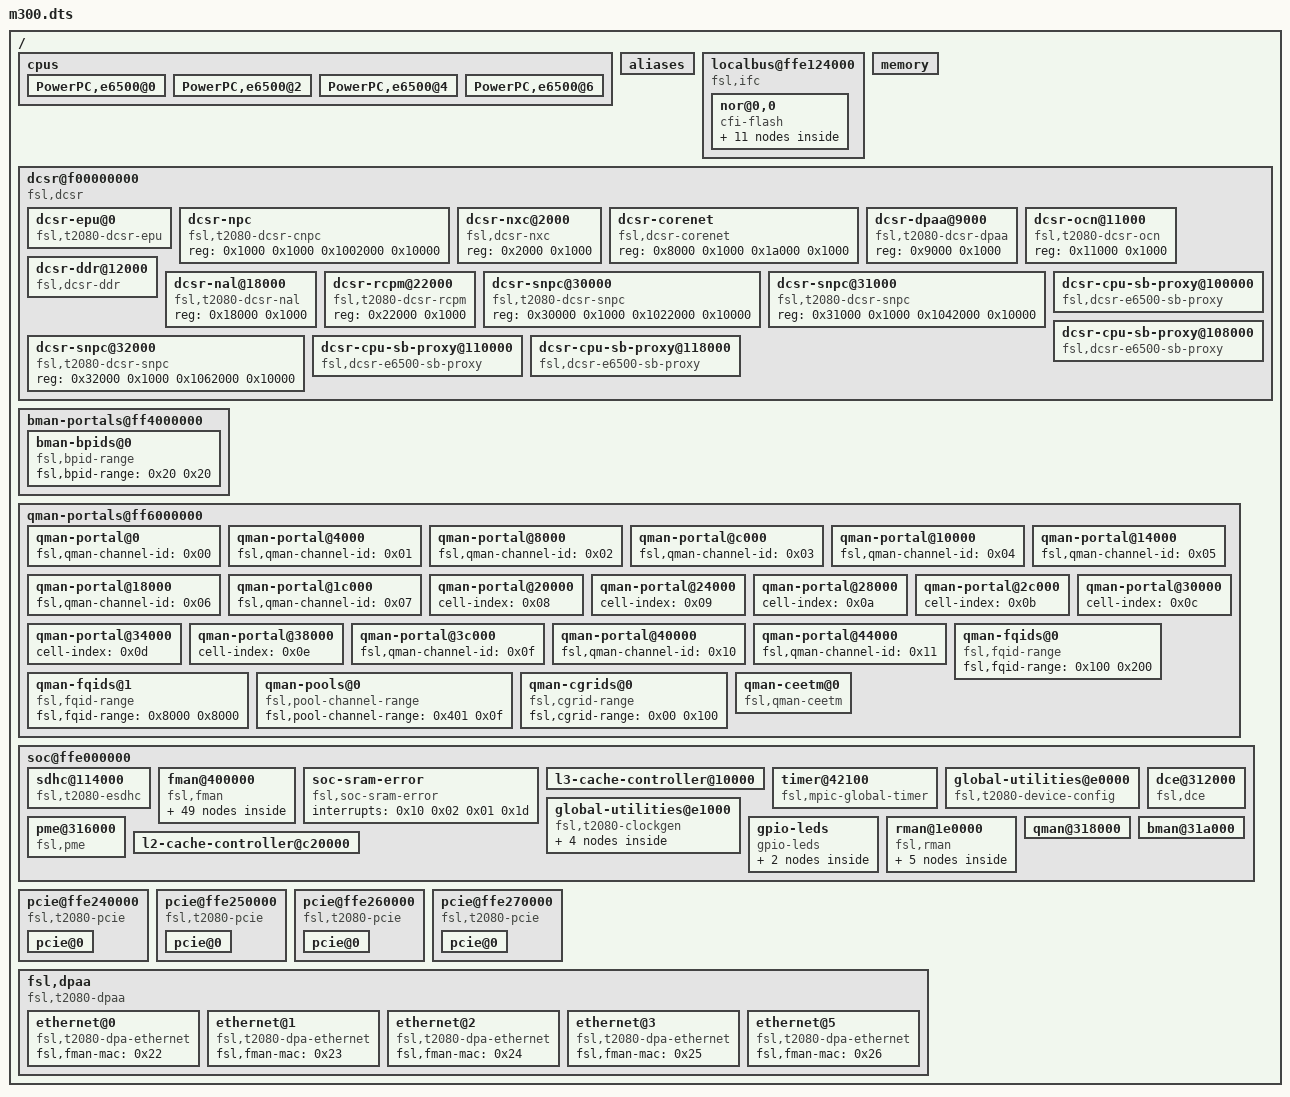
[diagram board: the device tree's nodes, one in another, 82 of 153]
/dts-v1/;

/ {
	cpus {
		PowerPC,e6500@0 {
			device_type = "cpu";
			reg = <0x00 0x01>;
			next-level-cache = <0x03>;
			linux,phandle = <0x05>;
			phandle = <0x05>;
		};

		PowerPC,e6500@2 {
			device_type = "cpu";
			reg = <0x02 0x03>;
			clocks = <0x02>;
			next-level-cache = <0x03>;
			linux,phandle = <0x06>;
			phandle = <0x06>;
		};

		PowerPC,e6500@4 {
			device_type = "cpu";
			reg = <0x04 0x05>;
			clocks = <0x02>;
			next-level-cache = <0x03>;
			linux,phandle = <0x07>;
			phandle = <0x07>;
		};

		PowerPC,e6500@6 {
			device_type = "cpu";
			reg = <0x06 0x07>;
			clocks = <0x02>;
			next-level-cache = <0x03>;
			linux,phandle = <0x08>;
			phandle = <0x08>;
		};
	};

	aliases {
		ccsr = "/soc@ffe000000";
		dcsr = "/dcsr@f00000000";
		serial0 = "/soc@ffe000000/serial@11c500";
		serial1 = "/soc@ffe000000/serial@11c600";
		serial2 = "/soc@ffe000000/serial@11d500";
		serial3 = "/soc@ffe000000/serial@11d600";
		crypto = "/soc@ffe000000/crypto@300000";
		rman = "/soc@ffe000000/rman@1e0000";
		dce = "/soc@ffe000000/dce@312000";
		pme = "/soc@ffe000000/pme@316000";
		qman = "/soc@ffe000000/qman@318000";
		bman = "/soc@ffe000000/bman@31a000";
		fman0 = "/soc@ffe000000/fman@400000";
		ethernet0 = "/soc@ffe000000/fman@400000/ethernet@e0000";
		ethernet1 = "/soc@ffe000000/fman@400000/ethernet@e2000";
		ethernet2 = "/soc@ffe000000/fman@400000/ethernet@e4000";
		ethernet3 = "/soc@ffe000000/fman@400000/ethernet@e6000";
		ethernet4 = "/soc@ffe000000/fman@400000/ethernet@f2000";
		pci0 = "/pcie@ffe240000";
		pci1 = "/pcie@ffe250000";
		pci2 = "/pcie@ffe260000";
		pci3 = "/pcie@ffe270000";
		usb0 = "/soc@ffe000000/usb@210000";
		usb1 = "/soc@ffe000000/usb@211000";
		dma0 = "/soc@ffe000000/dma@100300";
		dma1 = "/soc@ffe000000/dma@101300";
		dma2 = "/soc@ffe000000/dma@102300";
		sdhc = "/soc@ffe000000/sdhc@114000";
		phy_sgmii_0 = "/soc@ffe000000/fman@400000/mdio@fc000/ethernet-phy@01";
		phy_sgmii_1 = "/soc@ffe000000/fman@400000/mdio@fc000/ethernet-phy@02";
		phy_sgmii_2 = "/soc@ffe000000/fman@400000/mdio@fc000/ethernet-phy@03";
	};

	localbus@ffe124000 {
		reg = <0x0f 0xfe124000 0x00 0x2000>;
		ranges = <0x00 0x00 0x0f 0xefc00000 0x400000>;
		#address-cells = <0x02>;
		#size-cells = <0x01>;
		compatible = "fsl,ifc\0simple-bus";
		interrupts = <0x19 0x02 0x00 0x00>;

		nor@0,0 {
			#address-cells = <0x01>;
			#size-cells = <0x01>;
			compatible = "cfi-flash";
			reg = <0x00 0x00 0x400000>;
			bank-width = <0x02>;
			device-width = <0x01>;

			partition@00000000 {
				reg = <0x00 0x10000>;
				label = "NOR (RW) LANNER RCW Code";
			};

			partition@00010000 {
				reg = <0x10000 0x20000>;
				label = "NOR (RW) WG CFG0";
			};

			partition@00030000 {
				reg = <0x30000 0x10000>;
				label = "NOR (RW) WG CFG1";
			};

			partition@00040000 {
				reg = <0x40000 0x10000>;
				label = "NOR (RW) WG MFG DATA";
			};

			partition@00050000 {
				reg = <0x50000 0xb0000>;
				label = "NOR (RW) WG bootOpt Data & reserved";
			};

			partition@00100000 {
				reg = <0x100000 0xb0000>;
				label = "NOR (RW) WG extra reserved 1";
			};

			partition@001B0000 {
				reg = <0x1b0000 0xb0000>;
				label = "NOR (RW) WG extra reserved 2";
			};

			partition@00260000 {
				reg = <0x260000 0xc0000>;
				label = "NOR (RW) WG U-Boot FAILSAFE";
			};

			partition@00320000 {
				reg = <0x320000 0x10000>;
				label = "NOR (RW) FMAN";
			};

			partition@00330000 {
				reg = <0x330000 0x10000>;
				label = "NOR (RW) WG U-Boot ENV";
			};

			partition@00340000 {
				reg = <0x340000 0xc0000>;
				label = "NOR (RW) WG U-Boot Image";
			};
		};
	};

	memory {
		device_type = "memory";
	};

	dcsr@f00000000 {
		ranges = <0x00 0x0f 0x00 0x1072000>;
		#address-cells = <0x01>;
		#size-cells = <0x01>;
		compatible = "fsl,dcsr\0simple-bus";

		dcsr-epu@0 {
			compatible = "fsl,t2080-dcsr-epu\0fsl,dcsr-epu";
			interrupts = <0x34 0x02 0x00 0x00 0x54 0x02 0x00 0x00 0x55 0x02 0x00 0x00 0x5e 0x02 0x00 0x00 0x5f 0x02 0x00 0x00>;
			reg = <0x00 0x1000>;
		};

		dcsr-npc {
			compatible = "fsl,t2080-dcsr-cnpc\0fsl,dcsr-cnpc";
			reg = <0x1000 0x1000 0x1002000 0x10000>;
		};

		dcsr-nxc@2000 {
			compatible = "fsl,dcsr-nxc";
			reg = <0x2000 0x1000>;
		};

		dcsr-corenet {
			compatible = "fsl,dcsr-corenet";
			reg = <0x8000 0x1000 0x1a000 0x1000>;
		};

		dcsr-dpaa@9000 {
			compatible = "fsl,t2080-dcsr-dpaa\0fsl,dcsr-dpaa";
			reg = <0x9000 0x1000>;
		};

		dcsr-ocn@11000 {
			compatible = "fsl,t2080-dcsr-ocn\0fsl,dcsr-ocn";
			reg = <0x11000 0x1000>;
		};

		dcsr-ddr@12000 {
			compatible = "fsl,dcsr-ddr";
			dev-handle = <0x04>;
			reg = <0x12000 0x1000>;
		};

		dcsr-nal@18000 {
			compatible = "fsl,t2080-dcsr-nal\0fsl,dcsr-nal";
			reg = <0x18000 0x1000>;
		};

		dcsr-rcpm@22000 {
			compatible = "fsl,t2080-dcsr-rcpm\0fsl,dcsr-rcpm";
			reg = <0x22000 0x1000>;
		};

		dcsr-snpc@30000 {
			compatible = "fsl,t2080-dcsr-snpc\0fsl,dcsr-snpc";
			reg = <0x30000 0x1000 0x1022000 0x10000>;
		};

		dcsr-snpc@31000 {
			compatible = "fsl,t2080-dcsr-snpc\0fsl,dcsr-snpc";
			reg = <0x31000 0x1000 0x1042000 0x10000>;
		};

		dcsr-snpc@32000 {
			compatible = "fsl,t2080-dcsr-snpc\0fsl,dcsr-snpc";
			reg = <0x32000 0x1000 0x1062000 0x10000>;
		};

		dcsr-cpu-sb-proxy@100000 {
			compatible = "fsl,dcsr-e6500-sb-proxy\0fsl,dcsr-cpu-sb-proxy";
			cpu-handle = <0x05>;
			reg = <0x100000 0x1000 0x101000 0x1000>;
		};

		dcsr-cpu-sb-proxy@108000 {
			compatible = "fsl,dcsr-e6500-sb-proxy\0fsl,dcsr-cpu-sb-proxy";
			cpu-handle = <0x06>;
			reg = <0x108000 0x1000 0x109000 0x1000>;
		};

		dcsr-cpu-sb-proxy@110000 {
			compatible = "fsl,dcsr-e6500-sb-proxy\0fsl,dcsr-cpu-sb-proxy";
			cpu-handle = <0x07>;
			reg = <0x110000 0x1000 0x111000 0x1000>;
		};

		dcsr-cpu-sb-proxy@118000 {
			compatible = "fsl,dcsr-e6500-sb-proxy\0fsl,dcsr-cpu-sb-proxy";
			cpu-handle = <0x08>;
			reg = <0x118000 0x1000 0x119000 0x1000>;
		};
	};

	bman-portals@ff4000000 {

		bman-bpids@0 {
			compatible = "fsl,bpid-range";
			fsl,bpid-range = <0x20 0x20>;
		};
	};

	qman-portals@ff6000000 {
		qman-portal@0 {
			fsl,qman-channel-id = <0x00>;
		};

		qman-portal@4000 {
			fsl,qman-channel-id = <0x01>;
		};

		qman-portal@8000 {
			fsl,qman-channel-id = <0x02>;
		};

		qman-portal@c000 {
			fsl,qman-channel-id = <0x03>;
		};

		qman-portal@10000 {
			fsl,qman-channel-id = <0x04>;
		};

		qman-portal@14000 {
			fsl,qman-channel-id = <0x05>;
		};

		qman-portal@18000 {
			fsl,qman-channel-id = <0x06>;
		};

		qman-portal@1c000 {
			fsl,qman-channel-id = <0x07>;
		};

		qman-portal@20000 {
			cell-index = <0x08>;
		};

		qman-portal@24000 {
			cell-index = <0x09>;
		};

		qman-portal@28000 {
			cell-index = <0x0a>;
		};

		qman-portal@2c000 {
			cell-index = <0x0b>;
		};

		qman-portal@30000 {
			cell-index = <0x0c>;
		};

		qman-portal@34000 {
			cell-index = <0x0d>;
		};

		qman-portal@38000 {
			cell-index = <0x0e>;
		};

		qman-portal@3c000 {
			fsl,qman-channel-id = <0x0f>;
		};

		qman-portal@40000 {
			fsl,qman-channel-id = <0x10>;
		};

		qman-portal@44000 {
			fsl,qman-channel-id = <0x11>;
		};

		qman-fqids@0 {
			compatible = "fsl,fqid-range";
			fsl,fqid-range = <0x100 0x200>;
		};

		qman-fqids@1 {
			compatible = "fsl,fqid-range";
			fsl,fqid-range = <0x8000 0x8000>;
		};

		qman-pools@0 {
			compatible = "fsl,pool-channel-range";
			fsl,pool-channel-range = <0x401 0x0f>;
		};

		qman-cgrids@0 {
			compatible = "fsl,cgrid-range";
			fsl,cgrid-range = <0x00 0x100>;
		};

		qman-ceetm@0 {
			compatible = "fsl,qman-ceetm";
			fsl,ceetm-lfqid-range = <0xf00000 0x1000>;
			fsl,ceetm-sp-range = <0x00 0x0c>;
			fsl,ceetm-lni-range = <0x00 0x08>;
			fsl,ceetm-channel-range = <0x00 0x20>;
		};
	};

	soc@ffe000000 {


		sdhc@114000 {
			voltage-ranges = <0x708 0x708 0xce4 0xce4>;
			compatible = "fsl,t2080-esdhc\0fsl,esdhc";
			reg = <0x114000 0x1000>;
			interrupts = <0x30 0x02 0x00 0x00>;
			clock-frequency = <0x00>;
			sdhci,auto-cmd12;
		};

		fman@400000 {
			#address-cells = <0x01>;
			#size-cells = <0x01>;
			cell-index = <0x00>;
			compatible = "fsl,fman\0simple-bus";
			ranges = <0x00 0x400000 0x100000>;
			reg = <0x400000 0x100000>;
			clock-frequency = <0x00>;
			interrupts = <0x60 0x02 0x00 0x00 0x10 0x02 0x01 0x01>;

			ethernet@e0000 {
				phy-handle = <0x09>;
				phy-connection-type = "sgmii";
				cell-index = <0x00>;
				compatible = "fsl,fman-memac";
				reg = <0xe0000 0x1000>;
				fsl,port-handles = <0x0a 0x0b>;
				ptimer-handle = <0x0c>;
				linux,phandle = <0x23>;
				phandle = <0x23>;
			};

			ethernet@e2000 {
				phy-handle = <0x0d>;
				phy-connection-type = "sgmii";
				cell-index = <0x01>;
				compatible = "fsl,fman-memac";
				reg = <0xe2000 0x1000>;
				fsl,port-handles = <0x0e 0x0f>;
				ptimer-handle = <0x0c>;
				linux,phandle = <0x24>;
				phandle = <0x24>;
			};

			ethernet@e4000 {
				fixed-link = <0x10 0x01 0x3e8 0x00 0x00>;
				phy-connection-type = "rgmii";
				cell-index = <0x02>;
				compatible = "fsl,fman-memac";
				reg = <0xe4000 0x1000>;
				fsl,port-handles = <0x10 0x11>;
				ptimer-handle = <0x0c>;
				linux,phandle = <0x25>;
				phandle = <0x25>;
			};

			ethernet@e6000 {
				fixed-link = <0x04 0x01 0x3e8 0x00 0x00>;
				phy-connection-type = "rgmii";
				cell-index = <0x03>;
				compatible = "fsl,fman-memac";
				reg = <0xe6000 0x1000>;
				fsl,port-handles = <0x12 0x13>;
				ptimer-handle = <0x0c>;
				linux,phandle = <0x26>;
				phandle = <0x26>;
			};

			ethernet@f2000 {
				phy-handle = <0x14>;
				phy-connection-type = "sgmii";
				cell-index = <0x01>;
				compatible = "fsl,fman-memac";
				reg = <0xf2000 0x1000>;
				fsl,port-handles = <0x15 0x16>;
				linux,phandle = <0x22>;
				phandle = <0x22>;
			};

			cc {
				compatible = "fsl,fman-cc";
			};

			bmi@80000 {
				compatible = "fsl,fman-bmi";
				reg = <0x80000 0x400>;
			};

			qmi@80400 {
				compatible = "fsl,fman-qmi";
				reg = <0x80400 0x400>;
			};

			port@82000 {
				cell-index = <0x00>;
				compatible = "fsl,fman-port-oh";
				reg = <0x82000 0x1000>;
				fsl,qman-channel-id = <0x809>;
			};

			port@83000 {
				cell-index = <0x01>;
				compatible = "fsl,fman-port-oh";
				reg = <0x83000 0x1000>;
				fsl,qman-channel-id = <0x80a>;
			};

			port@84000 {
				cell-index = <0x02>;
				compatible = "fsl,fman-port-oh";
				reg = <0x84000 0x1000>;
				fsl,qman-channel-id = <0x80b>;
			};

			port@85000 {
				cell-index = <0x03>;
				compatible = "fsl,fman-port-oh";
				reg = <0x85000 0x1000>;
				fsl,qman-channel-id = <0x80c>;
			};

			port@86000 {
				cell-index = <0x04>;
				compatible = "fsl,fman-port-oh";
				reg = <0x86000 0x1000>;
				fsl,qman-channel-id = <0x80d>;
			};

			port@87000 {
				cell-index = <0x05>;
				compatible = "fsl,fman-port-oh";
				reg = <0x87000 0x1000>;
				fsl,qman-channel-id = <0x80e>;
			};

			policer@c0000 {
				compatible = "fsl,fman-policer";
				reg = <0xc0000 0x1000>;
			};

			keygen@c1000 {
				compatible = "fsl,fman-keygen";
				reg = <0xc1000 0x1000>;
			};

			dma@c2000 {
				compatible = "fsl,fman-dma";
				reg = <0xc2000 0x1000>;
			};

			fpm@c3000 {
				compatible = "fsl,fman-fpm";
				reg = <0xc3000 0x1000>;
			};

			parser@c7000 {
				compatible = "fsl,fman-parser";
				reg = <0xc7000 0x1000>;
			};

			vsps@dc000 {
				compatible = "fsl,fman-vsps";
				reg = <0xdc000 0x1000>;
			};

			mdio@fd000 {
				#address-cells = <0x01>;
				#size-cells = <0x00>;
				compatible = "fsl,fman-memac-mdio";
				reg = <0xfd000 0x1000>;
			};

			rtc@fe000 {
				compatible = "fsl,fman-rtc";
				reg = <0xfe000 0x1000>;
				linux,phandle = <0x0c>;
				phandle = <0x0c>;
			};

			port@88000 {
				cell-index = <0x00>;
				compatible = "fsl,fman-port-1g-rx";
				reg = <0x88000 0x1000>;
				linux,phandle = <0x0a>;
				phandle = <0x0a>;
			};

			port@a8000 {
				cell-index = <0x00>;
				compatible = "fsl,fman-port-1g-tx";
				reg = <0xa8000 0x1000>;
				fsl,qman-channel-id = <0x802>;
				linux,phandle = <0x0b>;
				phandle = <0x0b>;
			};

			mdio@e1000 {
				#address-cells = <0x01>;
				#size-cells = <0x00>;
				compatible = "fsl,fman-memac-mdio";
				reg = <0xe1000 0x1000>;
			};

			port@89000 {
				cell-index = <0x01>;
				compatible = "fsl,fman-port-1g-rx";
				reg = <0x89000 0x1000>;
				linux,phandle = <0x0e>;
				phandle = <0x0e>;
			};

			port@a9000 {
				cell-index = <0x01>;
				compatible = "fsl,fman-port-1g-tx";
				reg = <0xa9000 0x1000>;
				fsl,qman-channel-id = <0x803>;
				linux,phandle = <0x0f>;
				phandle = <0x0f>;
			};

			mdio@e3000 {
				#address-cells = <0x01>;
				#size-cells = <0x00>;
				compatible = "fsl,fman-memac-mdio";
				reg = <0xe3000 0x1000>;
			};

			port@8a000 {
				cell-index = <0x02>;
				compatible = "fsl,fman-port-1g-rx";
				reg = <0x8a000 0x1000>;
				linux,phandle = <0x10>;
				phandle = <0x10>;
			};

			port@aa000 {
				cell-index = <0x02>;
				compatible = "fsl,fman-port-1g-tx";
				reg = <0xaa000 0x1000>;
				fsl,qman-channel-id = <0x804>;
				linux,phandle = <0x11>;
				phandle = <0x11>;
			};

			mdio@e5000 {
				#address-cells = <0x01>;
				#size-cells = <0x00>;
				compatible = "fsl,fman-memac-mdio";
				reg = <0xe5000 0x1000>;
			};

			port@8b000 {
				cell-index = <0x03>;
				compatible = "fsl,fman-port-1g-rx";
				reg = <0x8b000 0x1000>;
				linux,phandle = <0x12>;
				phandle = <0x12>;
			};

			port@ab000 {
				cell-index = <0x03>;
				compatible = "fsl,fman-port-1g-tx";
				reg = <0xab000 0x1000>;
				fsl,qman-channel-id = <0x805>;
				linux,phandle = <0x13>;
				phandle = <0x13>;
			};

			mdio@e7000 {
				#address-cells = <0x01>;
				#size-cells = <0x00>;
				compatible = "fsl,fman-memac-mdio";
				reg = <0xe7000 0x1000>;
			};

			port@8c000 {
				cell-index = <0x04>;
				compatible = "fsl,fman-port-1g-rx";
				reg = <0x8c000 0x1000>;
				linux,phandle = <0x17>;
				phandle = <0x17>;
			};

			port@ac000 {
				cell-index = <0x04>;
				compatible = "fsl,fman-port-1g-tx";
				reg = <0xac000 0x1000>;
				fsl,qman-channel-id = <0x806>;
				linux,phandle = <0x18>;
				phandle = <0x18>;
			};

			ethernet@e8000 {
				cell-index = <0x04>;
				compatible = "fsl,fman-memac";
				reg = <0xe8000 0x1000>;
				fsl,port-handles = <0x17 0x18>;
				ptimer-handle = <0x0c>;
			};

			mdio@e9000 {
				#address-cells = <0x01>;
				#size-cells = <0x00>;
				compatible = "fsl,fman-memac-mdio";
				reg = <0xe9000 0x1000>;
			};

			port@8d000 {
				cell-index = <0x05>;
				compatible = "fsl,fman-port-1g-rx";
				reg = <0x8d000 0x1000>;
				linux,phandle = <0x19>;
				phandle = <0x19>;
			};

			port@ad000 {
				cell-index = <0x05>;
				compatible = "fsl,fman-port-1g-tx";
				reg = <0xad000 0x1000>;
				fsl,qman-channel-id = <0x807>;
				linux,phandle = <0x1a>;
				phandle = <0x1a>;
			};

			ethernet@ea000 {
				cell-index = <0x05>;
				compatible = "fsl,fman-memac";
				reg = <0xea000 0x1000>;
				fsl,port-handles = <0x19 0x1a>;
				ptimer-handle = <0x0c>;
			};

			mdio@eb000 {
				#address-cells = <0x01>;
				#size-cells = <0x00>;
				compatible = "fsl,fman-memac-mdio";
				reg = <0xeb000 0x1000>;
			};

			port@90000 {
				cell-index = <0x00>;
				compatible = "fsl,fman-port-10g-rx";
				reg = <0x90000 0x1000>;
				linux,phandle = <0x1b>;
				phandle = <0x1b>;
			};

			port@b0000 {
				cell-index = <0x00>;
				compatible = "fsl,fman-port-10g-tx";
				reg = <0xb0000 0x1000>;
				fsl,qman-channel-id = <0x800>;
				linux,phandle = <0x1c>;
				phandle = <0x1c>;
			};

			ethernet@f0000 {
				cell-index = <0x00>;
				compatible = "fsl,fman-memac";
				reg = <0xf0000 0x1000>;
				fsl,port-handles = <0x1b 0x1c>;
			};

			mdio@f1000 {
				#address-cells = <0x01>;
				#size-cells = <0x00>;
				compatible = "fsl,fman-memac-mdio";
				reg = <0xf1000 0x1000>;
			};

			port@91000 {
				cell-index = <0x01>;
				compatible = "fsl,fman-port-10g-rx";
				reg = <0x91000 0x1000>;
				linux,phandle = <0x15>;
				phandle = <0x15>;
			};

			port@b1000 {
				cell-index = <0x01>;
				compatible = "fsl,fman-port-10g-tx";
				reg = <0xb1000 0x1000>;
				fsl,qman-channel-id = <0x801>;
				linux,phandle = <0x16>;
				phandle = <0x16>;
			};

			mdio@f3000 {
				#address-cells = <0x01>;
				#size-cells = <0x00>;
				compatible = "fsl,fman-memac-mdio";
				reg = <0xf3000 0x1000>;
			};
		};

		soc-sram-error {
			compatible = "fsl,soc-sram-error";
			interrupts = <0x10 0x02 0x01 0x1d>;
		};

		l3-cache-controller@10000 {
			linux,phandle = <0x21>;
			phandle = <0x21>;
		};

		timer@42100 {
			compatible = "fsl,mpic-global-timer";
			reg = <0x42100 0x100 0x42300 0x04>;
			interrupts = <0x04 0x00 0x03 0x00 0x05 0x00 0x03 0x00 0x06 0x00 0x03 0x00 0x07 0x00 0x03 0x00>;
		};

		global-utilities@e0000 {
			compatible = "fsl,t2080-device-config\0fsl,qoriq-device-config-2.0";
			reg = <0xe0000 0xe00>;
			fsl,has-rstcr;
			fsl,liodn-bits = <0x0c>;
		};

		global-utilities@e1000 {
			compatible = "fsl,t2080-clockgen\0fsl,qoriq-clockgen-2.0\0fixed-clock";
			reg = <0xe1000 0x1000>;
			clock-output-names = "sysclk";
			#clock-cells = <0x00>;
			#address-cells = <0x01>;
			#size-cells = <0x00>;
			linux,phandle = <0x1d>;
			phandle = <0x1d>;

			pll0@800 {
				#clock-cells = <0x01>;
				reg = <0x800>;
				compatible = "fsl,core-pll-clock";
				clocks = <0x1d>;
				clock-output-names = "pll0\0pll0-div2\0pll0-div4";
				linux,phandle = <0x1e>;
				phandle = <0x1e>;
			};

			pll1@820 {
				#clock-cells = <0x01>;
				reg = <0x820>;
				compatible = "fsl,core-pll-clock";
				clocks = <0x1d>;
				clock-output-names = "pll1\0pll1-div2\0pll1-div4";
				linux,phandle = <0x1f>;
				phandle = <0x1f>;
			};

			mux0@0 {
				#clock-cells = <0x00>;
				reg = <0x00>;
				compatible = "fsl,core-mux-clock";
				clocks = <0x1e 0x00 0x1e 0x01 0x1e 0x02 0x1f 0x00 0x1f 0x01 0x1f 0x02>;
				clock-names = "pll0_0\0pll0_1\0pll0_2\0pll1_0\0pll1_1\0pll1_2";
				clock-output-names = "cmux0";
				linux,phandle = <0x02>;
				phandle = <0x02>;
			};

			mux1@20 {
				#clock-cells = <0x00>;
				reg = <0x20>;
				compatible = "fsl,core-mux-clock";
				clocks = <0x1e 0x00 0x1e 0x01 0x1e 0x02 0x1f 0x00 0x1f 0x01 0x1f 0x02>;
				clock-names = "pll0_0\0pll0_1\0pll0_2\0pll1_0\0pll1_1\0pll1_2";
				clock-output-names = "cmux1";
			};
		};

		gpio-leds {
			compatible = "gpio-leds";

			led28 {
				label = "led28";
				gpios = <0x20 0x1c 0x01>;
				default-state = "on";
			};

			led29 {
				label = "led29";
				gpios = <0x20 0x1d 0x01>;
				default-state = "on";
			};
		};

		rman@1e0000 {
			compatible = "fsl,rman";
			#address-cells = <0x01>;
			#size-cells = <0x01>;
			ranges = <0x00 0x1e0000 0x20000>;
			reg = <0x1e0000 0x20000>;
			interrupts = <0x10 0x02 0x01 0x0b>;
			fsl,qman-channels-id = <0x820 0x821>;

			inbound-block@0 {
				compatible = "fsl,rman-inbound-block";
				reg = <0x00 0x800>;
			};

			global-cfg@b00 {
				compatible = "fsl,rman-global-cfg";
				reg = <0xb00 0x500>;
			};

			inbound-block@1000 {
				compatible = "fsl,rman-inbound-block";
				reg = <0x1000 0x800>;
			};

			inbound-block@2000 {
				compatible = "fsl,rman-inbound-block";
				reg = <0x2000 0x800>;
			};

			inbound-block@3000 {
				compatible = "fsl,rman-inbound-block";
				reg = <0x3000 0x800>;
			};
		};

		dce@312000 {
			compatible = "fsl,dce";
			reg = <0x312000 0x10000>;
			interrupts = <0x10 0x02 0x01 0x04>;
		};

		pme@316000 {
			compatible = "fsl,pme";
			reg = <0x316000 0x10000>;
			interrupts = <0x10 0x02 0x01 0x05>;
		};

		qman@318000 {
		};

		bman@31a000 {
		};

		l2-cache-controller@c20000 {
			reg = <0xc20000 0x40000>;
			next-level-cache = <0x21>;
			linux,phandle = <0x03>;
			phandle = <0x03>;
		};
	};

	pcie@ffe240000 {
		reg = <0x0f 0xfe240000 0x00 0x10000>;
		ranges = <0x2000000 0x00 0xe0000000 0x0c 0x00 0x00 0x20000000 0x1000000 0x00 0x00 0x0f 0xf8000000 0x00 0x10000>;
		compatible = "fsl,t2080-pcie\0fsl,qoriq-pcie-v3.0\0fsl,qoriq-pcie";
		device_type = "pci";
		#size-cells = <0x02>;
		#address-cells = <0x03>;
		bus-range = <0x00 0xff>;
		interrupts = <0x14 0x02 0x00 0x00>;

		pcie@0 {
			ranges = <0x2000000 0x00 0xe0000000 0x2000000 0x00 0xe0000000 0x00 0x20000000 0x1000000 0x00 0x00 0x1000000 0x00 0x00 0x00 0x10000>;
			reg = <0x00 0x00 0x00 0x00 0x00>;
			#interrupt-cells = <0x01>;
			#size-cells = <0x02>;
			#address-cells = <0x03>;
			device_type = "pci";
			interrupts = <0x14 0x02 0x00 0x00>;
			interrupt-map-mask = <0xf800 0x00 0x00 0x07>;
			interrupt-map = <0x00 0x00 0x00 0x01 0x01 0x28 0x01 0x00 0x00 0x00 0x00 0x00 0x02 0x01 0x01 0x01 0x00 0x00 0x00 0x00 0x00 0x03 0x01 0x02 0x01 0x00 0x00 0x00 0x00 0x00 0x04 0x01 0x03 0x01 0x00 0x00>;
		};
	};

	pcie@ffe250000 {
		reg = <0x0f 0xfe250000 0x00 0x10000>;
		ranges = <0x2000000 0x00 0xe0000000 0x0c 0x20000000 0x00 0x10000000 0x1000000 0x00 0x00 0x0f 0xf8010000 0x00 0x10000>;
		compatible = "fsl,t2080-pcie\0fsl,qoriq-pcie-v3.0\0fsl,qoriq-pcie";
		device_type = "pci";
		#size-cells = <0x02>;
		#address-cells = <0x03>;
		bus-range = <0x00 0xff>;
		interrupts = <0x15 0x02 0x00 0x00>;

		pcie@0 {
			ranges = <0x2000000 0x00 0xe0000000 0x2000000 0x00 0xe0000000 0x00 0x20000000 0x1000000 0x00 0x00 0x1000000 0x00 0x00 0x00 0x10000>;
			reg = <0x00 0x00 0x00 0x00 0x00>;
			#interrupt-cells = <0x01>;
			#size-cells = <0x02>;
			#address-cells = <0x03>;
			device_type = "pci";
			interrupts = <0x15 0x02 0x00 0x00>;
			interrupt-map-mask = <0xf800 0x00 0x00 0x07>;
			interrupt-map = <0x00 0x00 0x00 0x01 0x01 0x29 0x01 0x00 0x00 0x00 0x00 0x00 0x02 0x01 0x05 0x01 0x00 0x00 0x00 0x00 0x00 0x03 0x01 0x06 0x01 0x00 0x00 0x00 0x00 0x00 0x04 0x01 0x07 0x01 0x00 0x00>;
		};
	};

	pcie@ffe260000 {
		reg = <0x0f 0xfe260000 0x00 0x1000>;
		ranges = <0x2000000 0x00 0xe0000000 0x0c 0x30000000 0x00 0x10000000 0x1000000 0x00 0x00 0x0f 0xf8020000 0x00 0x10000>;
		compatible = "fsl,t2080-pcie\0fsl,qoriq-pcie-v3.0\0fsl,qoriq-pcie";
		device_type = "pci";
		#size-cells = <0x02>;
		#address-cells = <0x03>;
		bus-range = <0x00 0xff>;
		interrupts = <0x16 0x02 0x00 0x00>;

		pcie@0 {
			ranges = <0x2000000 0x00 0xe0000000 0x2000000 0x00 0xe0000000 0x00 0x20000000 0x1000000 0x00 0x00 0x1000000 0x00 0x00 0x00 0x10000>;
			reg = <0x00 0x00 0x00 0x00 0x00>;
			#interrupt-cells = <0x01>;
			#size-cells = <0x02>;
			#address-cells = <0x03>;
			device_type = "pci";
			interrupts = <0x16 0x02 0x00 0x00>;
			interrupt-map-mask = <0xf800 0x00 0x00 0x07>;
			interrupt-map = <0x00 0x00 0x00 0x01 0x01 0x2a 0x01 0x00 0x00 0x00 0x00 0x00 0x02 0x01 0x09 0x01 0x00 0x00 0x00 0x00 0x00 0x03 0x01 0x0a 0x01 0x00 0x00 0x00 0x00 0x00 0x04 0x01 0x0b 0x01 0x00 0x00>;
		};
	};

	pcie@ffe270000 {
		reg = <0x0f 0xfe270000 0x00 0x10000>;
		ranges = <0x2000000 0x00 0xe0000000 0x0c 0x40000000 0x00 0x10000000 0x1000000 0x00 0x00 0x0f 0xf8030000 0x00 0x10000>;
		compatible = "fsl,t2080-pcie\0fsl,qoriq-pcie-v3.0\0fsl,qoriq-pcie";
		device_type = "pci";
		#size-cells = <0x02>;
		#address-cells = <0x03>;
		bus-range = <0x00 0xff>;
		interrupts = <0x17 0x02 0x00 0x00>;

		pcie@0 {
			ranges = <0x2000000 0x00 0xe0000000 0x2000000 0x00 0xe0000000 0x00 0x20000000 0x1000000 0x00 0x00 0x1000000 0x00 0x00 0x00 0x10000>;
			reg = <0x00 0x00 0x00 0x00 0x00>;
			#interrupt-cells = <0x01>;
			#size-cells = <0x02>;
			#address-cells = <0x03>;
			device_type = "pci";
			interrupts = <0x17 0x02 0x00 0x00>;
			interrupt-map-mask = <0xf800 0x00 0x00 0x07>;
			interrupt-map = <0x00 0x00 0x00 0x01 0x01 0x2b 0x01 0x00 0x00 0x00 0x00 0x00 0x02 0x01 0x00 0x01 0x00 0x00 0x00 0x00 0x00 0x03 0x01 0x04 0x01 0x00 0x00 0x00 0x00 0x00 0x04 0x01 0x08 0x01 0x00 0x00>;
		};
	};

	fsl,dpaa {
		compatible = "fsl,t2080-dpaa\0fsl,dpaa";

		ethernet@0 {
			compatible = "fsl,t2080-dpa-ethernet\0fsl,dpa-ethernet";
			fsl,fman-mac = <0x22>;
		};

		ethernet@1 {
			compatible = "fsl,t2080-dpa-ethernet\0fsl,dpa-ethernet";
			fsl,fman-mac = <0x23>;
		};

		ethernet@2 {
			compatible = "fsl,t2080-dpa-ethernet\0fsl,dpa-ethernet";
			fsl,fman-mac = <0x24>;
		};

		ethernet@3 {
			compatible = "fsl,t2080-dpa-ethernet\0fsl,dpa-ethernet";
			fsl,fman-mac = <0x25>;
		};

		ethernet@5 {
			compatible = "fsl,t2080-dpa-ethernet\0fsl,dpa-ethernet";
			fsl,fman-mac = <0x26>;
		};
	};
};
